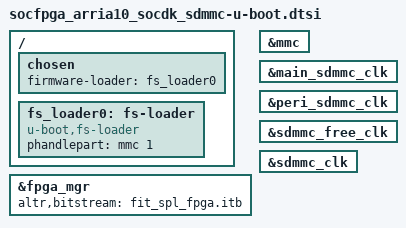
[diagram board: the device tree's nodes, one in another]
// SPDX-License-Identifier: GPL-2.0
/*
 * Copyright (C) 2014-2015, 2020 Intel. All rights reserved.
 */

#include "socfpga_arria10_socdk_sdmmc_handoff.h"
#include "socfpga_arria10-handoff.dtsi"
#include "socfpga_arria10_handoff_u-boot.dtsi"
#include "socfpga_arria10_socdk-u-boot.dtsi"

/ {
	chosen {
		firmware-loader = <&fs_loader0>;
	};

	fs_loader0: fs-loader {
		u-boot,dm-all;
		compatible = "u-boot,fs-loader";
		phandlepart = <&mmc 1>;
	};
};

&fpga_mgr {
	u-boot,dm-all;
	altr,bitstream = "fit_spl_fpga.itb";
};

&mmc {
	u-boot,dm-all;
};

/* Clock available early */
&main_sdmmc_clk {
	u-boot,dm-all;
};

&peri_sdmmc_clk {
	u-boot,dm-all;
};

&sdmmc_free_clk {
	u-boot,dm-all;
};

&sdmmc_clk {
	u-boot,dm-all;
};
